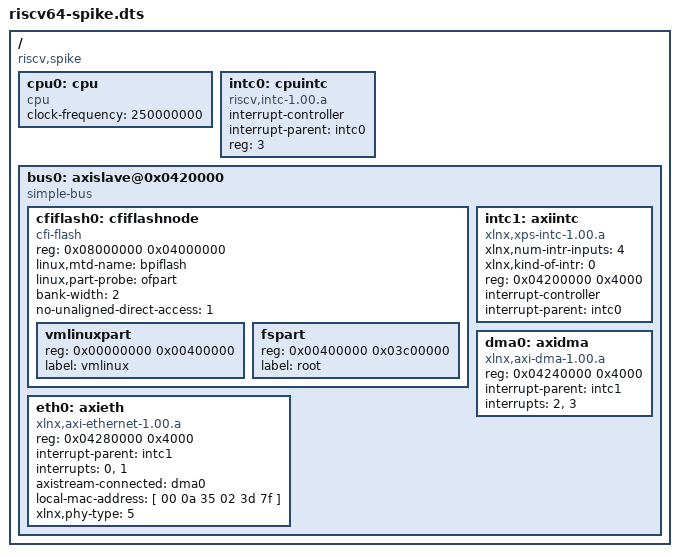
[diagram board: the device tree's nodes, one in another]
/*
 *  Copyright (C) 2016 Jamey Hicks
 *
 * This software is licensed under the terms of the GNU General Public
 * License version 2, as published by the Free Software Foundation, and
 * may be copied, distributed, and modified under those terms.
 *
 * This program is distributed in the hope that it will be useful,
 * but WITHOUT ANY WARRANTY; without even the implied warranty of
 * MERCHANTABILITY or FITNESS FOR A PARTICULAR PURPOSE.  See the
 * GNU General Public License for more details.
 */
/dts-v1/;
/ {
	compatible = "riscv,spike";

	#address-cells = <1>;
	#size-cells = <1>;

	cpu0: cpu {
	      compatible = "cpu";
	      clock-frequency = <250000000>;
	};

	intc0: cpuintc {
		#address-cells = <1>;
		#size-cells = <1>;
		#interrupt-cells = <1>;
		compatible = "riscv,intc-1.00.a";
		interrupt-controller;
		interrupt-parent = <&intc0>; // root interrupt-controller is its own parent
		reg = <3>;
	};

	bus0: axislave@0x0420000 {
		compatible = "simple-bus";
		ranges; /*  = <0 0 0x08000000 0x08000000>;*/
 	        #interrupt-cells = <3>;
		#address-cells = <1>;
		#size-cells = <1>;

		cfiflash0: cfiflashnode {
			#address-cells = <1>;
			#size-cells = <1>;
			compatible = "cfi-flash";
			reg = <0x08000000 0x04000000>;
			linux,mtd-name = "bpiflash";
			linux,part-probe = "ofpart";
			bank-width = <2>;
			no-unaligned-direct-access = <1>;
			vmlinuxpart {
				#address-cells = <1>;
				#size-cells = <1>;
				reg = <0x00000000 0x00400000>;
				label = "vmlinux";
			};
			fspart {
				#address-cells = <1>;
				#size-cells = <1>;
				reg = <0x00400000 0x03c00000>;
				label = "root";
			};
		};

		intc1: axiintc {
			#address-cells = <1>;
			#size-cells = <1>;
			#interrupt-cells = <1>;
			compatible = "xlnx,xps-intc-1.00.a";
			xlnx,num-intr-inputs = <4>;
			xlnx,kind-of-intr = <0>;
			reg = <0x04200000 0x4000>;
			interrupt-controller;
			interrupt-parent = <&intc0>;
		};

		dma0: axidma {
			#address-cells = <1>;
			#size-cells = <1>;
			#interrupt-cells = <1>;
			compatible = "xlnx,axi-dma-1.00.a";
			reg = <0x04240000 0x4000>;
			status = "ok";
			interrupt-parent = <&intc1>;
			interrupts = <2>, <3>; // TX, RX
		};

		eth0: axieth {
			#address-cells = <1>;
			#size-cells = <1>;
			#interrupt-cells = <1>;
			compatible = "xlnx,axi-ethernet-1.00.a";
			reg = <0x04280000 0x4000>;
			status = "ok";
			interrupt-parent = <&intc1>;
			interrupts = <0>, <1>; // Subsystem, MAC
			//clocks = <&clkc 31>, <&clkc 31>, <&clkc 14>;
			clock-names = "pclk", "hclk", "tx_clk";
			axistream-connected = <&dma0>;
			local-mac-address = [ 00 0a 35 02 3d 7f ];
			xlnx,phy-type = <5>;
		};
	};
};
